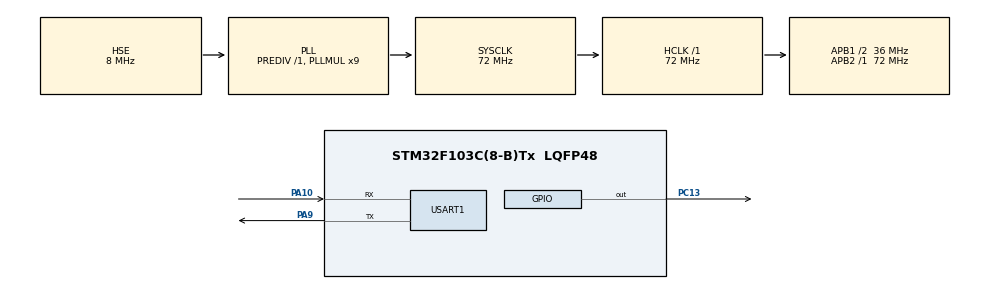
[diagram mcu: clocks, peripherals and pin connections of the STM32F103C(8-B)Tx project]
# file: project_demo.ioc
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Mcu.Family=STM32F1
Mcu.Name=STM32F103C(8-B)Tx
Mcu.Package=LQFP48
NVIC.PriorityGroup=NVIC_PRIORITYGROUP_4
NVIC.USART1_IRQn=true\:1\:0\:true\:false\:true\:true\:true\:true
PA10.Mode=Asynchronous
PA10.Signal=USART1_RX
PA13.Mode=Serial_Wire
PA13.Signal=SYS_JTMS-SWDIO
PA14.Mode=Serial_Wire
PA14.Signal=SYS_JTCK-SWCLK
PA9.Mode=Asynchronous
PA9.Signal=USART1_TX
PC13-TAMPER-RTC.GPIO_PuPd=GPIO_NOPULL
PC13-TAMPER-RTC.Signal=GPIO_Output
PD0-OSC_IN.Mode=HSE-External-Oscillator
PD0-OSC_IN.Signal=RCC_OSC_IN
PD1-OSC_OUT.Mode=HSE-External-Oscillator
PD1-OSC_OUT.Signal=RCC_OSC_OUT
ProjectManager.HeapSize=0x200
ProjectManager.StackSize=0x400
ProjectManager.TargetToolchain=MDK-ARM V5.32
RCC.AHBFreq_Value=72000000
RCC.APB1CLKDivider=RCC_HCLK_DIV2
RCC.APB1Freq_Value=36000000
RCC.APB1TimFreq_Value=72000000
RCC.APB2Freq_Value=72000000
RCC.APB2TimFreq_Value=72000000
RCC.HCLKFreq_Value=72000000
RCC.PLLMUL=RCC_PLL_MUL9
RCC.PLLSourceVirtual=RCC_PLLSOURCE_HSE
RCC.SYSCLKFreq_VALUE=72000000
RCC.SYSCLKSource=RCC_SYSCLKSOURCE_PLLCLK
RCC.USBFreq_Value=72000000
TIM4.Period=499
TIM4.Prescaler=7999
USART1.VirtualMode=VM_ASYNC
VP_TIM4_VS_ClockSourceINT.Mode=Internal
board=custom

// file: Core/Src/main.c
/* USER CODE BEGIN Header */
/**
		******************************************************************************
		* @file           : main.c
		* @brief          : Main program body
		******************************************************************************
		* @attention
		*
		* Copyright (c) 2025 STMicroelectronics.
		* All rights reserved.
		*
		* This software is licensed under terms that can be found in the LICENSE file
		* in the root directory of this software component.
		* If no LICENSE file comes with this software, it is provided AS-IS.
		*
		******************************************************************************
		*/
/* USER CODE END Header */
#include "main.h"

TIM_HandleTypeDef htim4;
UART_HandleTypeDef huart1;
uint8_t rx_buffer[7]; // Buffer để lưu dữ liệu nhận được
uint16_t rx_index = 0; // Chỉ số theo dõi vị trí trong buffer
uint8_t rx_byte;       // Biến để lưu byte nhận được

void SystemClock_Config(void);
static void MX_GPIO_Init(void);
static void MX_TIM4_Init(void);
static void MX_USART1_UART_Init(void);

/* USER CODE BEGIN 0 */

void HAL_UART_RxCpltCallback(UART_HandleTypeDef *huart) {
    if (huart->Instance == USART1) {
            rx_buffer[rx_index++] = rx_byte;
            if (rx_byte == ' ') {
                HAL_UART_Transmit(&huart1, rx_buffer, rx_index, HAL_MAX_DELAY);
                rx_index = 0;
        }
        HAL_UART_Receive_IT(&huart1, &rx_byte, 1);
    }
}

//void HAL_UART_RxCpltCallback(UART_HandleTypeDef *huart) {
//    if (huart->Instance == USART1) {
//        rx_byte = rx_buffer[rx_index];
//        if (rx_byte == ' ') {
//            if (rx_index > 0) {
//                HAL_UART_Transmit(&huart1, rx_buffer, rx_index, 1);
//            }
//						  rx_index = 0;
//    		} else {
//						rx_index++;
//						rx_buffer[rx_index] = rx_byte;
//								}
//        HAL_UART_Receive_IT(&huart1, &rx_buffer[rx_index], 1);
//    }

//}

/* USER CODE END 0 */

int main(void)
{

    /* MCU Configuration--------------------------------------------------------*/

    /* Reset of all peripherals, Initializes the Flash interface and the Systick. */
    HAL_Init();

    /* Configure the system clock */
    SystemClock_Config();

    /* Initialize all configured peripherals */
    MX_GPIO_Init();
    MX_TIM4_Init();
    MX_USART1_UART_Init();
    /* USER CODE BEGIN 2 */
    HAL_UART_Receive_IT(&huart1, &rx_byte, 1); // Bắt đầu nhận byte đầu tiên
    /* USER CODE END 2 */

    /* Infinite loop */
    while (1)
    {

    }
}

void SystemClock_Config(void)
{
    RCC_OscInitTypeDef RCC_OscInitStruct = {0};
    RCC_ClkInitTypeDef RCC_ClkInitStruct = {0};

    /** Initializes the RCC Oscillators according to the specified parameters
    * in the RCC_OscInitTypeDef structure.
    */
    RCC_OscInitStruct.OscillatorType = RCC_OSCILLATORTYPE_HSE;
    RCC_OscInitStruct.HSEState = RCC_HSE_ON;
    RCC_OscInitStruct.HSEPredivValue = RCC_HSE_PREDIV_DIV1;
    RCC_OscInitStruct.HSIState = RCC_HSI_ON;
    RCC_OscInitStruct.PLL.PLLState = RCC_PLL_ON;
    RCC_OscInitStruct.PLL.PLLSource = RCC_PLLSOURCE_HSE;
    RCC_OscInitStruct.PLL.PLLMUL = RCC_PLL_MUL9;
    if (HAL_RCC_OscConfig(&RCC_OscInitStruct) != HAL_OK)
    {
        Error_Handler();
    }

    /** Initializes the CPU, AHB and APB buses clocks
    */
    RCC_ClkInitStruct.ClockType = RCC_CLOCKTYPE_HCLK|RCC_CLOCKTYPE_SYSCLK
                                |RCC_CLOCKTYPE_PCLK1|RCC_CLOCKTYPE_PCLK2;
    RCC_ClkInitStruct.SYSCLKSource = RCC_SYSCLKSOURCE_PLLCLK;
    RCC_ClkInitStruct.AHBCLKDivider = RCC_SYSCLK_DIV1;
    RCC_ClkInitStruct.APB1CLKDivider = RCC_HCLK_DIV2;
    RCC_ClkInitStruct.APB2CLKDivider = RCC_HCLK_DIV1;

    if (HAL_RCC_ClockConfig(&RCC_ClkInitStruct, FLASH_LATENCY_2) != HAL_OK)
    {
        Error_Handler();
    }
}

static void MX_TIM4_Init(void)
{

    TIM_ClockConfigTypeDef sClockSourceConfig = {0};
    TIM_MasterConfigTypeDef sMasterConfig = {0};

    htim4.Instance = TIM4;
    htim4.Init.Prescaler = 7999;
    htim4.Init.CounterMode = TIM_COUNTERMODE_UP;
    htim4.Init.Period = 499;
    htim4.Init.ClockDivision = TIM_CLOCKDIVISION_DIV1;
    htim4.Init.AutoReloadPreload = TIM_AUTORELOAD_PRELOAD_DISABLE;
    if (HAL_TIM_Base_Init(&htim4) != HAL_OK)
    {
        Error_Handler();
    }
    sClockSourceConfig.ClockSource = TIM_CLOCKSOURCE_INTERNAL;
    if (HAL_TIM_ConfigClockSource(&htim4, &sClockSourceConfig) != HAL_OK)
    {
        Error_Handler();
    }
    sMasterConfig.MasterOutputTrigger = TIM_TRGO_RESET;
    sMasterConfig.MasterSlaveMode = TIM_MASTERSLAVEMODE_DISABLE;
    if (HAL_TIMEx_MasterConfigSynchronization(&htim4, &sMasterConfig) != HAL_OK)
    {
        Error_Handler();
    }

}

static void MX_USART1_UART_Init(void)
{

    huart1.Instance = USART1;
    huart1.Init.BaudRate = 115200;
    huart1.Init.WordLength = UART_WORDLENGTH_8B;
    huart1.Init.StopBits = UART_STOPBITS_1;
    huart1.Init.Parity = UART_PARITY_NONE;
    huart1.Init.Mode = UART_MODE_TX_RX;
    huart1.Init.HwFlowCtl = UART_HWCONTROL_NONE;
    huart1.Init.OverSampling = UART_OVERSAMPLING_16;
    if (HAL_UART_Init(&huart1) != HAL_OK)
    {
        Error_Handler();
    }

}

static void MX_GPIO_Init(void)
{
    GPIO_InitTypeDef GPIO_InitStruct = {0};

    /* GPIO Ports Clock Enable */
    __HAL_RCC_GPIOC_CLK_ENABLE();
    __HAL_RCC_GPIOD_CLK_ENABLE();
    __HAL_RCC_GPIOA_CLK_ENABLE();

    /*Configure GPIO pin Output Level */
    HAL_GPIO_WritePin(GPIOC, GPIO_PIN_13, GPIO_PIN_RESET);

    /*Configure GPIO pin : PC13 */
    GPIO_InitStruct.Pin = GPIO_PIN_13;
    GPIO_InitStruct.Mode = GPIO_MODE_OUTPUT_PP;
    GPIO_InitStruct.Pull = GPIO_NOPULL;
    GPIO_InitStruct.Speed = GPIO_SPEED_FREQ_LOW;
    HAL_GPIO_Init(GPIOC, &GPIO_InitStruct);

}

void Error_Handler(void)
{
    __disable_irq();
    while (1)
    {
    }
}

#ifdef  USE_FULL_ASSERT
/**
  * @brief  Reports the name of the source file and the source line number
  * where the assert_param error has occurred.
  * @param  file: pointer to the source file name
  * @param  line: assert_param error line source number
  * @retval None
  */
void assert_failed(uint8_t *file, uint32_t line)
{
    /* USER CODE BEGIN 6 */
    /* User can add your own implementation to report the file name and line number,
       ex: printf("Wrong parameters value: file %s on line %d\r\n", file, line) */
    /* USER CODE END 6 */
}
#endif /* USE_FULL_ASSERT */
